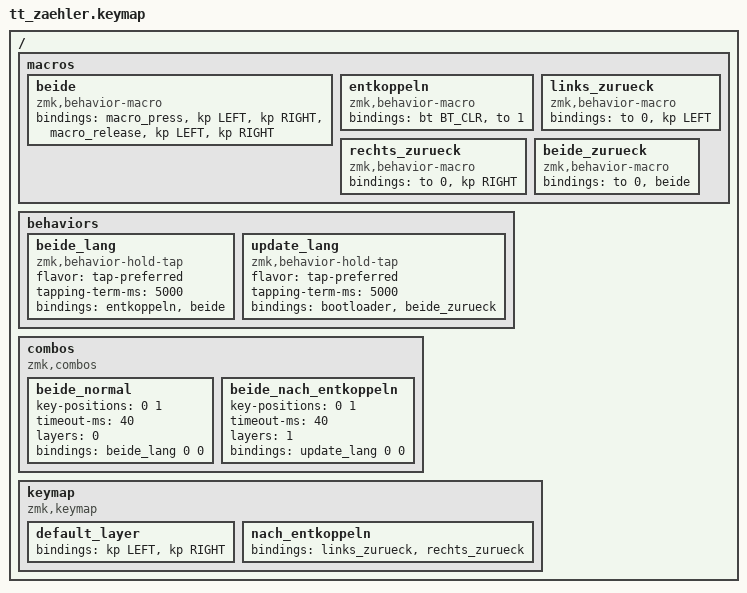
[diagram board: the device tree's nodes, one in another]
// Linker Taster = Pfeil links, rechter Taster = Pfeil rechts – die Standardtasten der App.
// Beide Taster zugleich: kurz = Neustart in der App (beide Pfeile), 5 s halten = Bluetooth-Kopplung
// löschen, damit sich ein anderes Handy verbinden kann (ZMK lehnt sonst jedes zweite Gerät ab).
// Notfall-Update: direkt danach beide Taster nochmal 5 s halten = Update-Modus (vorher per USB an
// den Rechner, dann erscheint das Laufwerk NICENANO, .uf2 draufziehen; ohne USB startet die Box
// nach 3 s normal neu). Jeder andere Druck nach dem Entkoppeln zählt normal und beendet das.
#include <behaviors.dtsi>
#include <dt-bindings/zmk/keys.h>
#include <dt-bindings/zmk/bt.h>

/ {
    macros {
        beide: beide {
            compatible = "zmk,behavior-macro";
            #binding-cells = <0>;
            bindings
                = <&macro_press &kp LEFT &kp RIGHT>
                , <&macro_release &kp LEFT &kp RIGHT>
                ;
        };

        entkoppeln: entkoppeln {
            compatible = "zmk,behavior-macro";
            #binding-cells = <0>;
            bindings = <&bt BT_CLR>, <&to 1>;
        };

        links_zurueck: links_zurueck {
            compatible = "zmk,behavior-macro";
            #binding-cells = <0>;
            bindings = <&to 0>, <&kp LEFT>;
        };

        rechts_zurueck: rechts_zurueck {
            compatible = "zmk,behavior-macro";
            #binding-cells = <0>;
            bindings = <&to 0>, <&kp RIGHT>;
        };

        beide_zurueck: beide_zurueck {
            compatible = "zmk,behavior-macro";
            #binding-cells = <0>;
            bindings = <&to 0>, <&beide>;
        };
    };

    behaviors {
        beide_lang: beide_lang {
            compatible = "zmk,behavior-hold-tap";
            #binding-cells = <2>;
            flavor = "tap-preferred";
            tapping-term-ms = <5000>;
            bindings = <&entkoppeln>, <&beide>;
        };

        update_lang: update_lang {
            compatible = "zmk,behavior-hold-tap";
            #binding-cells = <2>;
            flavor = "tap-preferred";
            tapping-term-ms = <5000>;
            bindings = <&bootloader>, <&beide_zurueck>;
        };
    };

    combos {
        compatible = "zmk,combos";
        beide_normal {
            key-positions = <0 1>;
            timeout-ms = <40>; // so lange wartet ein einzelner Druck auf den zweiten Taster
            layers = <0>;
            bindings = <&beide_lang 0 0>;
        };
        beide_nach_entkoppeln {
            key-positions = <0 1>;
            timeout-ms = <40>;
            layers = <1>;
            bindings = <&update_lang 0 0>;
        };
    };

    keymap {
        compatible = "zmk,keymap";

        default_layer {
            bindings = <&kp LEFT &kp RIGHT>;
        };

        nach_entkoppeln {
            bindings = <&links_zurueck &rechts_zurueck>;
        };
    };
};
